AUTOSAR XML (schema 4-0-3)
package /AUTOSAR_SecOC/SwComponentTypes
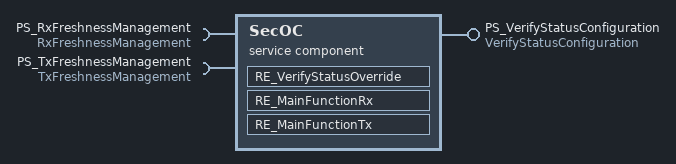
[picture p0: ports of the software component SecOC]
  service sw component type SecOC
    require port PS_RxFreshnessManagement: required-interface=RxFreshnessManagement
    provide port PS_VerifyStatusConfiguration: provided-interface=VerifyStatusConfiguration
    require port PS_TxFreshnessManagement: required-interface=TxFreshnessManagement
    behavior SecOCInternalBehavior: handle-termination-and-restart=NO-SUPPORT
      operation invoked event EV_VerifyStatusOverride: start-on-event=RE_VerifyStatusOverride, operation=PS_VerifyStatusConfiguration.VerifyStatusOverride
      runnable RE_VerifyStatusOverride: arguments=[symbol=freshnessValueId, symbol=overrideStatus, symbol=numberOfMessagesToOverride], symbol=SecOC_VerifyStatusOverride
      runnable RE_MainFunctionRx: symbol=SecOC_MainFunctionRx
        sync call SSCP_GetRxFreshness: operation=PS_RxFreshnessManagement.GetRxFreshness, timeout=0
      runnable RE_MainFunctionTx: symbol=SecOC_MainFunctionTx
        sync call SSCP_GetTxFreshness: operation=PS_TxFreshnessManagement.GetTxFreshness, timeout=0
        sync call SSCP_SPduTxConfirmation: operation=PS_TxFreshnessManagement.SPduTxConfirmation, timeout=0
package /EB_SecOC/SwcImplementations
  swc implementation SecOCImpl: programming-language=C, sw-version=2.8.1, vendor-id=1, behavior=SecOCInternalBehavior
    code-descriptors:
      code SecOCCode: artifact-descriptors=autosar-engineering-object={short-label=EngObject, category=SWSRC}
    resource consumption Resources
      memory section CODE: sw-addrmethod=CODE
